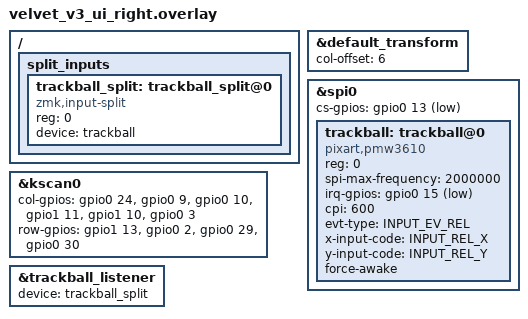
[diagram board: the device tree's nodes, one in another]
#include "velvet_v3_ui.dtsi"
#include <zephyr/dt-bindings/input/input-event-codes.h>

&default_transform {
    col-offset = <6>;
};

&kscan0 {
    col-gpios
        = <&gpio0 24 GPIO_ACTIVE_HIGH>
        , <&gpio0 9 GPIO_ACTIVE_HIGH>
        , <&gpio0 10 GPIO_ACTIVE_HIGH>
        , <&gpio1 11 GPIO_ACTIVE_HIGH>
        , <&gpio1 10 GPIO_ACTIVE_HIGH>
        , <&gpio0 3 GPIO_ACTIVE_HIGH>
        ;
};

&kscan0 {
    row-gpios
        = <&gpio1 13 (GPIO_ACTIVE_HIGH | GPIO_PULL_DOWN)>
        , <&gpio0 2 (GPIO_ACTIVE_HIGH | GPIO_PULL_DOWN)>
        , <&gpio0 29 (GPIO_ACTIVE_HIGH | GPIO_PULL_DOWN)>
        , <&gpio0 30 (GPIO_ACTIVE_HIGH | GPIO_PULL_DOWN)>
        ;
};

&spi0 {
    status = "okay";
    cs-gpios = <&gpio0 13 GPIO_ACTIVE_LOW>;

    trackball: trackball@0 {
        status = "okay";
        compatible = "pixart,pmw3610";
        reg = <0>;
        spi-max-frequency = <2000000>;
        irq-gpios = <&gpio0 15 (GPIO_ACTIVE_LOW | GPIO_PULL_UP)>;
        cpi = <600>;
        evt-type = <INPUT_EV_REL>;
        x-input-code = <INPUT_REL_X>;
        y-input-code = <INPUT_REL_Y>;

        force-awake;
        /* keep the sensor awake while ZMK activity state is ACTIVE,
           fallback to normal downshift mode after ZMK goes into IDLE / SLEEP mode.
           thus, the sensor would be a `wakeup-source` */
    };
};

/ {
    split_inputs {
        #address-cells = <1>;
        #size-cells = <0>;

        trackball_split: trackball_split@0 {
            compatible = "zmk,input-split";
            reg = <0>;
        };
    };
};

// Overrides for the input-split child node
&trackball_split {
    device = <&trackball>;

    // Optional
    // input-processors = <&zip_xy_transform (INPUT_TRANSFORM_XY_SWAP | INPUT_TRANSFORM_X_INVERT | INPUT_TRANSFORM_Y_INVERT)>;
};

&trackball_listener {
    status = "okay";
    device = <&trackball_split>;
};
